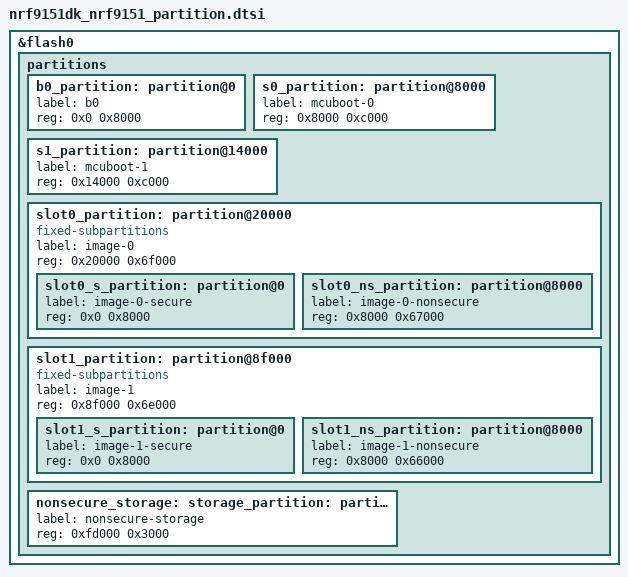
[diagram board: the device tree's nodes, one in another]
/*
 * Copyright (c) 2026 Nordic Semiconductor ASA
 *
 * SPDX-License-Identifier: LicenseRef-Nordic-5-Clause
 *
 * Flash partition layout for nRF9151DK with NSIB (b0) + MCUBoot.
 *
 * 0x0000_0000  b0 (NSIB)                    ( 32 kB)
 * 0x0000_8000  s0 (MCUBoot image, slot 0)   ( 48 kB)
 * 0x0001_4000  s1 (MCUBoot image, slot 1)   ( 48 kB)
 * 0x0002_0000  slot0 (primary app)          (444 kB)
 *   0x0002_0000  TF-M secure                ( 32 kB)
 *   0x0002_8000  Application (non-secure)   (412 kB - (MCUBoot swap sector + MCUboot trailer))
 * 0x0008_f000  slot1 (secondary app)        (440 kB)
 * 0x000f_d000  Non-secure storage           ( 12 kB)
 */

/delete-node/ &boot_partition;
/delete-node/ &slot0_partition;
/delete-node/ &slot1_partition;
/delete-node/ &tfm_ps_partition;
/delete-node/ &tfm_its_partition;
/delete-node/ &tfm_otp_partition;
/delete-node/ &storage_partition;

&flash0 {
	partitions {
		b0_partition: partition@0 {
			label = "b0";
			reg = <0x0 0x8000>;
		};

		s0_partition: partition@8000 {
			label = "mcuboot-0";
			reg = <0x8000 0xc000>;
		};

		s1_partition: partition@14000 {
			label = "mcuboot-1";
			reg = <0x14000 0xc000>;
		};

		slot0_partition: partition@20000 {
			compatible = "fixed-subpartitions";
			label = "image-0";
			reg = <0x20000 0x6f000>;
			ranges = <0x0 0x20000 0x6f000>;
			#address-cells = <1>;
			#size-cells = <1>;

			slot0_s_partition: partition@0 {
				label = "image-0-secure";
				reg = <0x0 0x8000>;
			};

			slot0_ns_partition: partition@8000 {
				label = "image-0-nonsecure";
				reg = <0x8000 0x67000>;
			};
		};

		slot1_partition: partition@8f000 {
			compatible = "fixed-subpartitions";
			label = "image-1";
			reg = <0x8f000 0x6e000>;
			ranges = <0x0 0x8f000 0x6e000>;
			#address-cells = <1>;
			#size-cells = <1>;

			slot1_s_partition: partition@0 {
				label = "image-1-secure";
				reg = <0x0 0x8000>;
			};

			slot1_ns_partition: partition@8000 {
				label = "image-1-nonsecure";
				reg = <0x8000 0x66000>;
			};
		};

		nonsecure_storage: storage_partition: partition@fd000 {
			label = "nonsecure-storage";
			reg = <0xfd000 0x3000>;
		};
	};
};
